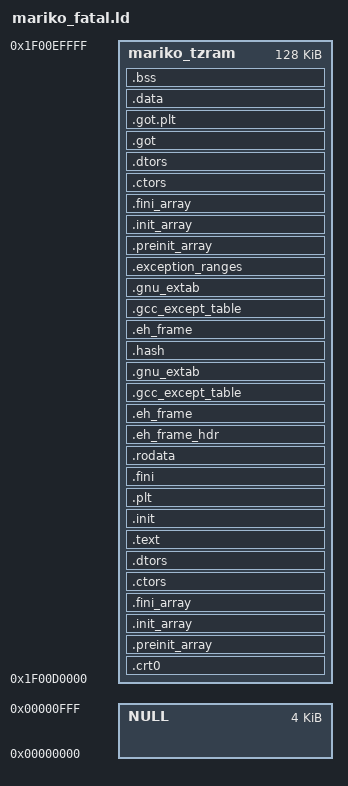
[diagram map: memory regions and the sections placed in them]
OUTPUT_ARCH(aarch64)
ENTRY(_start)

MEMORY
{
    NULL   : ORIGIN = 0,           LENGTH = 4K
    mariko_tzram  : ORIGIN = 0x1F00D0000, LENGTH = 128K
}


SECTIONS
{
	/* =========== CODE section =========== */
	PROVIDE(__start__ = ORIGIN(mariko_tzram));
	. = __start__;
	__code_start = . ;

	.crt0 :
	{
		KEEP (*(.crt0 .crt0.*))
        KEEP (fatal_crt0_cpp.o(.text*))
		*(.crt0.rodata*)
        fatal_crt0_cpp.o(.rodata*)
		*(.crt0.data*)
        fatal_crt0_cpp.o(.data*)
		. = ALIGN(8);
	} >mariko_tzram

	.preinit_array ALIGN(8) :
	{
		PROVIDE (__preinit_array_start = .);
		KEEP (*(.preinit_array))
		PROVIDE (__preinit_array_end = .);
	} >mariko_tzram

	.init_array ALIGN(8) :
	{
		PROVIDE (__init_array_start = .);
		KEEP (*(SORT(.init_array.*)))
		KEEP (*(.init_array))
		PROVIDE (__init_array_end = .);
	} >mariko_tzram

	.fini_array ALIGN(8) :
	{
		PROVIDE (__fini_array_start = .);
		KEEP (*(.fini_array))
		KEEP (*(SORT(.fini_array.*)))
		PROVIDE (__fini_array_end = .);
	} >mariko_tzram

	.ctors ALIGN(8) :
	{
		KEEP (*crtbegin.o(.ctors)) /* MUST be first -- GCC requires it */
		KEEP (*(EXCLUDE_FILE (*crtend.o) .ctors))
		KEEP (*(SORT(.ctors.*)))
		KEEP (*(.ctors))
	} >mariko_tzram

	.dtors ALIGN(8) :
	{
		KEEP (*crtbegin.o(.dtors))
		KEEP (*(EXCLUDE_FILE (*crtend.o) .dtors))
		KEEP (*(SORT(.dtors.*)))
		KEEP (*(.dtors))
	} >mariko_tzram

	.text :
	{
		*(.text.unlikely .text.*_unlikely .text.unlikely.*)
		*(.text.exit .text.exit.*)
		*(.text.startup .text.startup.*)
		*(.text.hot .text.hot.*)
		*(.text .stub .text.* .gnu.linkonce.t.*)
		. = ALIGN(8);
	} >mariko_tzram

	.init :
	{
		KEEP( *(.init) )
		. = ALIGN(8);
	} >mariko_tzram

	.plt :
	{
		*(.plt)
		*(.iplt)
		. = ALIGN(8);
	} >mariko_tzram

	.fini :
	{
		KEEP( *(.fini) )
		. = ALIGN(8);
	} >mariko_tzram


	/* =========== RODATA section =========== */
	. = ALIGN(8);
	__rodata_start = . ;

	.rodata :
	{
		*(.rodata .rodata.* .gnu.linkonce.r.*)
		. = ALIGN(8);
	} >mariko_tzram

	.eh_frame_hdr     : { __eh_frame_hdr_start = .; *(.eh_frame_hdr) *(.eh_frame_entry .eh_frame_entry.*) __eh_frame_hdr_end = .; } >mariko_tzram
	.eh_frame         : ONLY_IF_RO { KEEP (*(.eh_frame)) *(.eh_frame.*) } >mariko_tzram
	.gcc_except_table : ONLY_IF_RO { *(.gcc_except_table .gcc_except_table.*) } >mariko_tzram
	.gnu_extab        : ONLY_IF_RO { *(.gnu_extab*) } >mariko_tzram

	.hash              : { *(.hash) } >mariko_tzram

	/* =========== DATA section =========== */
	. = ALIGN(8);
	__data_start = . ;

	.eh_frame : ONLY_IF_RW { KEEP (*(.eh_frame)) *(.eh_frame.*) } >mariko_tzram
	.gcc_except_table : ONLY_IF_RW { *(.gcc_except_table .gcc_except_table.*) } >mariko_tzram
	.gnu_extab : ONLY_IF_RW { *(.gnu_extab*) } >mariko_tzram
	.exception_ranges : ONLY_IF_RW { *(.exception_ranges .exception_ranges*) } >mariko_tzram

	.preinit_array ALIGN(8) :
	{
		PROVIDE (__preinit_array_start = .);
		KEEP (*(.preinit_array))
		PROVIDE (__preinit_array_end = .);
	} >mariko_tzram

	.init_array ALIGN(8) :
	{
		PROVIDE (__init_array_start = .);
		KEEP (*(SORT(.init_array.*)))
		KEEP (*(.init_array))
		PROVIDE (__init_array_end = .);
	} >mariko_tzram

	.fini_array ALIGN(8) :
	{
		PROVIDE (__fini_array_start = .);
		KEEP (*(.fini_array))
		KEEP (*(SORT(.fini_array.*)))
		PROVIDE (__fini_array_end = .);
	} >mariko_tzram

	.ctors ALIGN(8) :
	{
		KEEP (*crtbegin.o(.ctors)) /* MUST be first -- GCC requires it */
		KEEP (*(EXCLUDE_FILE (*crtend.o) .ctors))
		KEEP (*(SORT(.ctors.*)))
		KEEP (*(.ctors))
	} >mariko_tzram

	.dtors ALIGN(8) :
	{
		KEEP (*crtbegin.o(.dtors))
		KEEP (*(EXCLUDE_FILE (*crtend.o) .dtors))
		KEEP (*(SORT(.dtors.*)))
		KEEP (*(.dtors))
	} >mariko_tzram

	__got_start__ = .;

	.got            : { *(.got) *(.igot) } >mariko_tzram
	.got.plt        : { *(.got.plt)  *(.igot.plt) } >mariko_tzram

	__got_end__ = .;

	.data ALIGN(8) :
	{
		*(.data .data.* .gnu.linkonce.d.*)
		SORT(CONSTRUCTORS)
	} >mariko_tzram

	__bss_start__ = .;
	.bss ALIGN(8) :
	{
		*(.dynbss)
		*(.bss .bss.* .gnu.linkonce.b.*)
		*(COMMON)
		. = ALIGN(16);
	} >mariko_tzram
	__bss_end__ = .;

	__end__ = ABSOLUTE(.) ;

	/* ==================
	   ==== Metadata ====
	   ================== */

	/* Discard sections that difficult post-processing */
	/DISCARD/ : { *(.group .comment .note .interp) }

	/* Stabs debugging sections. */
	.stab          0 : { *(.stab) }
	.stabstr       0 : { *(.stabstr) }
	.stab.excl     0 : { *(.stab.excl) }
	.stab.exclstr  0 : { *(.stab.exclstr) }
	.stab.index    0 : { *(.stab.index) }
	.stab.indexstr 0 : { *(.stab.indexstr) }

	/* DWARF debug sections.
	   Symbols in the DWARF debugging sections are relative to the beginning
	   of the section so we begin them at 0. */

	/* DWARF 1 */
	.debug          0 : { *(.debug) }
	.line           0 : { *(.line) }

	/* GNU DWARF 1 extensions */
	.debug_srcinfo  0 : { *(.debug_srcinfo) }
	.debug_sfnames  0 : { *(.debug_sfnames) }

	/* DWARF 1.1 and DWARF 2 */
	.debug_aranges  0 : { *(.debug_aranges) }
	.debug_pubnames 0 : { *(.debug_pubnames) }

	/* DWARF 2 */
	.debug_info     0 : { *(.debug_info) }
	.debug_abbrev   0 : { *(.debug_abbrev) }
	.debug_line     0 : { *(.debug_line) }
	.debug_frame    0 : { *(.debug_frame) }
	.debug_str      0 : { *(.debug_str) }
	.debug_loc      0 : { *(.debug_loc) }
	.debug_macinfo  0 : { *(.debug_macinfo) }
}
